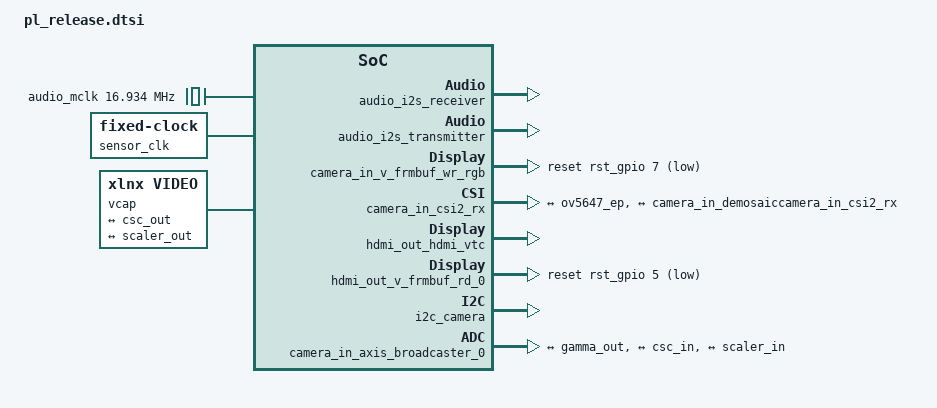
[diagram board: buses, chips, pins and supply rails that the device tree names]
/*
 * CAUTION: This file is automatically generated by Xilinx.
 * Version: XSCT 
 * Today is: Thu Jan  9 06:09:18 2025
 */
#include <dt-bindings/media/xilinx-vip.h>
#include <dt-bindings/gpio/gpio.h>


/ {
	amba_pl: amba_pl {
		#address-cells = <1>;
		#size-cells = <1>;
		compatible = "simple-bus";
		ranges ;
		audio_audio_formatter: audio_formatter@43c50000 {
			clock-names = "s_axi_lite_aclk", "m_axis_mm2s_aclk", "aud_mclk", "s_axis_s2mm_aclk";
			clocks = <&clkc 15>, <&clkc 15>, <&audio_mclk>, <&clkc 15>;
			compatible = "xlnx,audio-formatter-1.0", "xlnx,audio-formatter-1.0";
			interrupt-names = "irq_mm2s", "irq_s2mm";
			interrupt-parent = <&intc>;
			interrupts = <0 36 4 0 33 4>;
			reg = <0x43c50000 0x10000>;
			xlnx,include-mm2s = <0x1>;
			xlnx,include-s2mm = <0x1>;
			xlnx,max-num-channels-mm2s = <0x2>;
			xlnx,max-num-channels-s2mm = <0x2>;
			xlnx,mm2s-addr-width = <0x20>;
			xlnx,mm2s-async-clock = <0x0>;
			xlnx,mm2s-dataformat = <0x3>;
			xlnx,packing-mode-mm2s = <0x0>;
			xlnx,packing-mode-s2mm = <0x0>;
			xlnx,rx = <&audio_i2s_receiver>;
			xlnx,s2mm-addr-width = <0x20>;
			xlnx,s2mm-async-clock = <0x0>;
			xlnx,s2mm-dataformat = <0x1>;
			xlnx,tx = <&audio_i2s_transmitter>;
		};
		audio_mclk: audio_mclk {
			#clock-cells = <0>;
			clock-frequency = <16934404>;
			compatible = "fixed-clock";
		};
		audio_i2s_receiver: i2s_receiver@43c60000 {
			aud_mclk = <16934404>;
			clock-names = "s_axi_ctrl_aclk", "aud_mclk", "m_axis_aud_aclk";
			clocks = <&clkc 15>, <&audio_mclk>, <&clkc 15>;
			compatible = "xlnx,i2s-receiver-1.0", "xlnx,i2s-receiver-1.0";
			interrupt-names = "irq";
			interrupt-parent = <&intc>;
			interrupts = <0 35 4>;
			reg = <0x43c60000 0x10000>;
			xlnx,depth = <0x80>;
			xlnx,dwidth = <0x18>;
			xlnx,num-channels = <0x1>;
			xlnx,snd-pcm = <&audio_audio_formatter>;
		};
		audio_i2s_transmitter: i2s_transmitter@43c70000 {
			aud_mclk = <16934404>;
			clock-names = "s_axi_ctrl_aclk", "aud_mclk", "s_axis_aud_aclk";
			clocks = <&clkc 15>, <&audio_mclk>, <&clkc 15>;
			compatible = "xlnx,i2s-transmitter-1.0", "xlnx,i2s-transmitter-1.0";
			interrupt-names = "irq";
			interrupt-parent = <&intc>;
			interrupts = <0 34 4>;
			reg = <0x43c70000 0x10000>;
			xlnx,depth = <0x80>;
			xlnx,dwidth = <0x18>;
			xlnx,num-channels = <0x1>;
			xlnx,snd-pcm = <&audio_audio_formatter>;
		};
		axi_gpio_0: gpio@41210000 {
			#gpio-cells = <2>;
			clock-names = "s_axi_aclk";
			clocks = <&clkc 15>;
			compatible = "xlnx,axi-gpio-2.0", "xlnx,xps-gpio-1.00.a";
			gpio-controller ;
			reg = <0x41210000 0x10000>;
			xlnx,all-inputs = <0x0>;
			xlnx,all-inputs-2 = <0x0>;
			xlnx,all-outputs = <0x1>;
			xlnx,all-outputs-2 = <0x0>;
			xlnx,dout-default = <0x00000000>;
			xlnx,dout-default-2 = <0x00000000>;
			xlnx,gpio-width = <0x3>;
			xlnx,gpio2-width = <0x20>;
			xlnx,interrupt-present = <0x0>;
			xlnx,is-dual = <0x0>;
			xlnx,tri-default = <0xFFFFFFFF>;
			xlnx,tri-default-2 = <0xFFFFFFFF>;
		};
		vid_apclk: vid_apclk {
			#clock-cells = <0>;
			clock-frequency = <100000000>;
			compatible = "fixed-clock";
		};

		camera_in_v_frmbuf_wr_rgb: cam_preview {
			#dma-cells = <1>;
			clock-names = "ap_clk";
			clocks = <&vid_apclk>;
			compatible = "xlnx,v-frmbuf-wr-2.4", "xlnx,axi-frmbuf-wr-v2.2";
			interrupt-names = "interrupt";
			interrupt-parent = <&intc>;
			interrupts = <0 55 4>;
			reg = <0x83c20000 0x10000>;
			reset-gpios = <&rst_gpio 7 1>;
			xlnx,dma-addr-width = <32>;
			xlnx,dma-align = <16>;
			xlnx,max-height = <3072>;
			xlnx,max-width = <4096>;
			xlnx,pixels-per-clock = <2>;
			xlnx,s-axi-ctrl-addr-width = <0x7>;
			xlnx,s-axi-ctrl-data-width = <0x20>;
			xlnx,vid-formats = "rgb888", "bgr888";
			xlnx,video-width = <8>;
		};
		
		camera_in_csi2_rx: mipi_csi2_rx_subsystem@43c00000 {
			clock-names = "lite_aclk", "dphy_clk_200M", "video_aclk";
			clocks = <&clkc 15>, <&vid_apclk>, <&vid_apclk>;
			compatible = "xlnx,mipi-csi2-rx-subsystem-5.0";
			interrupt-names = "csirxss_csi_irq";
			interrupt-parent = <&intc>;
			interrupts = <0 54 4>;
			reg = <0x43c00000 0x2000>;
			video-reset-gpios = <&rst_gpio 4 1>;
			xlnx,axis-tdata-width = <32>;
			xlnx,csi-pxl-format = <0x2a>;
			xlnx,max-lanes = <2>;
			xlnx,ppc = <2>;
			xlnx,vfb ;
			mipi_csi_portscamera_in_csi2_rx: ports {
				#address-cells = <1>;
				#size-cells = <0>;
				mipi_csi_port0camera_in_csi2_rx: port@0 {
					/* Fill cfa-pattern=rggb for raw data types, other fields video-format,video-width user needs to fill */
					/* User need to add something like remote-endpoint=<&out> under the node csiss_in:endpoint */
					reg = <0>;
					xlnx,cfa-pattern = "rggb";
					xlnx,video-format = <XVIP_VF_MONO_SENSOR>;
					xlnx,video-width = <8>;
					mipi_csi_incamera_in_csi2_rx: endpoint {
						data-lanes = <1 2>;
						remote-endpoint=<&ov5647_ep>;
					};
				};
				mipi_csi_port1camera_in_csi2_rx: port@1 {
					/* Fill cfa-pattern=rggb for raw data types, other fields video-format and video-width user needs to fill */
					reg = <1>;
					xlnx,cfa-pattern = "rggb";
					xlnx,video-format = <XVIP_VF_MONO_SENSOR>;
					xlnx,video-width = <10>;
					mipi_csirx_outcamera_in_csi2_rx: endpoint {
						remote-endpoint = <&camera_in_demosaiccamera_in_csi2_rx>;
					};
				};
			};
		};
		camera_in_demosaic: demosaic {
			clock-names = "ap_clk";
			clocks = <&vid_apclk>;
			compatible = "xlnx,v-demosaic-1.1", "xlnx,v-demosaic";
			interrupt-names = "interrupt";
			interrupt-parent = <&intc>;
			interrupts = <0 30 4>;
			reg = <0x83c10000 0x10000>;
			reset-gpios = <&rst_gpio 3 1>;
			xlnx,max-height = <3072>;
			xlnx,max-width = <4096>;
			xlnx,s-axi-ctrl-addr-width = <0x6>;
			xlnx,s-axi-ctrl-data-width = <0x20>;
			demosaic_portscamera_in_demosaic: ports {
				#address-cells = <1>;
				#size-cells = <0>;
				demosaic_port0camera_in_demosaic: port@0 {
					/* For cfa-pattern=rggb user needs to fill as per BAYER format */
					reg = <0>;
					xlnx,cfa-pattern = "rggb";
					xlnx,video-width = <8>;
					camera_in_demosaiccamera_in_csi2_rx: endpoint {
						remote-endpoint = <&mipi_csirx_outcamera_in_csi2_rx>;
					};
				};
				demosaic_port1camera_in_demosaic: port@1 {
					/* For cfa-pattern=rggb user needs to fill as per BAYER format */
					reg = <1>;
					xlnx,cfa-pattern = "rggb";
					xlnx,video-width = <8>;
					demo_outcamera_in_demosaic: endpoint {
						remote-endpoint = <&camera_in_gamma_lutcamera_in_demosaic>;
					};
				};
			};
		};
		camera_in_gamma_lut: gamma_lut{
			clock-names = "ap_clk";
			clocks = <&vid_apclk>;
			compatible = "xlnx,v-gamma-lut-1.1", "xlnx,v-gamma-lut";
			interrupt-names = "interrupt";
			interrupt-parent = <&intc>;
			interrupts = <0 29 4>;
			reg = <0x83cb0000 0x10000>;
			reset-gpios = <&rst_gpio 2 1>;
			xlnx,max-height = <3072>;
			xlnx,max-width = <4096>;
			xlnx,s-axi-ctrl-addr-width = <13>;
			xlnx,s-axi-ctrl-data-width = <32>;
			gamma_portscamera_in_gamma_lut: ports {
				#address-cells = <1>;
				#size-cells = <0>;
				gamma_port0camera_in_gamma_lut: port@0 {
					reg = <0>;
					xlnx,video-width = <8>;
					camera_in_gamma_lutcamera_in_demosaic: endpoint {
						remote-endpoint = <&demo_outcamera_in_demosaic>;
					};
				};
				gamma_port1camera_in_gamma_lut: port@1 {
					reg = <1>;
					xlnx,video-width = <8>;
					gamma_out: endpoint {
						remote-endpoint = <&switch_in>;
					};
				};
			};
		};
		camera_in_frmbuf_wr: cam_capture {
			#dma-cells = <1>;
			clock-names = "ap_clk";
			clocks = <&vid_apclk>;
			compatible = "xlnx,v-frmbuf-wr-2.4", "xlnx,axi-frmbuf-wr-v2.2";
			interrupt-names = "interrupt";
			interrupt-parent = <&intc>;
			interrupts = <0 31 4>;
			reg = <0x83c40000 0x10000>;
			reset-gpios = <&rst_gpio 0 1>;
			xlnx,dma-addr-width = <32>;
			xlnx,dma-align = <16>;
			xlnx,max-height = <3072>;
			xlnx,max-width = <4096>;
			xlnx,pixels-per-clock = <2>;
			xlnx,s-axi-ctrl-addr-width = <0x7>;
			xlnx,s-axi-ctrl-data-width = <0x20>;
			xlnx,vid-formats = "rgb888", "bgr888", "y_u_v8";
			xlnx,video-width = <8>;
		};
		clk_wiz_0: clk_wiz@43c30000 {
			#clock-cells = <1>;
			clock-names = "s_axi_aclk", "clk_in1";
			clock-output-names = "0x43c30000-mlck";
			clocks = <&clkc 15>, <&clkc 15>;
			compatible = "xlnx,clk-wiz-6.0", "xlnx,clocking-wizard";
			reg = <0x43c30000 0x10000>;
			xlnx,nr-outputs = <1>;
			xlnx,speed-grade = <2>;
		};
		hdmi_out_clk_wiz_dyn: clk_wiz@43c80000 {
			#clock-cells = <1>;
			clock-names = "s_axi_aclk", "clk_in1";
			clock-output-names = "0x43c80000-hdmi_pclk", "0x43c80000-hdmi_pclk_5x";
			clocks = <&clkc 15>, <&clkc 15>;
			compatible = "xlnx,clk-wiz-6.0", "xlnx,clocking-wizard";
			reg = <0x43c80000 0x10000>;
			xlnx,nr-outputs = <2>;
			xlnx,speed-grade = <2>;
		};
		hdmi_out_hdmi_vtc: v_tc@43c90000 {
			clock-names = "clk", "s_axi_aclk";
			clocks = <&hdmi_pclk>, <&clkc 15>;
			compatible = "xlnx,v-tc-6.2", "xlnx,v-tc-6.1";
			interrupt-names = "irq";
			interrupt-parent = <&intc>;
			interrupts = <0 53 4>;
			reg = <0x43c90000 0x10000>;
			xlnx,generator ;
		};
		hdmi_pclk: hdmi_pclk {
			#clock-cells = <0>;
			clock-frequency = <148500000>;
			compatible = "fixed-clock";
		};
		hdmi_pclk_5x: hdmi_pclk_5x {
			#clock-cells = <0>;
			clock-frequency = <742500000>;
			compatible = "fixed-clock";
		};
		sensor_clk: sensor_clk {
			#clock-cells = <0>;
			clock-frequency = <25000000>;
			compatible = "fixed-clock";
		};
		hdmi_out_v_frmbuf_rd_0: v_frmbuf_rd@43ca0000 {
			#dma-cells = <1>;
			clock-names = "ap_clk";
			clocks = <&hdmi_pclk>;
			compatible = "xlnx,axi-frmbuf-rd-v2.2";
			interrupt-names = "interrupt";
			interrupt-parent = <&intc>;
			interrupts = <0 52 4>;
			reg = <0x43ca0000 0x10000>;
			reset-gpios = <&rst_gpio 5 1>;
			xlnx,dma-addr-width = <32>;
			xlnx,dma-align = <8>;
			xlnx,max-height = <1080>;
			xlnx,max-width = <1920>;
			xlnx,pixels-per-clock = <1>;
			xlnx,s-axi-ctrl-addr-width = <0x7>;
			xlnx,s-axi-ctrl-data-width = <0x20>;
			xlnx,vid-formats = "rgb888", "bgr888";
			xlnx,video-width = <8>;
		};
		i2c_camera: i2c@41600000 {
			#address-cells = <1>;
			#size-cells = <0>;
			clock-names = "s_axi_aclk";
			clocks = <&clkc 15>;
			compatible = "xlnx,axi-iic-2.1", "xlnx,xps-iic-2.00.a";
			interrupt-names = "iic2intc_irpt";
			interrupt-parent = <&intc>;
			interrupts = <0 32 4>;
			reg = <0x41600000 0x10000>;
		};
		rst_gpio: gpio@41220000 {
			#gpio-cells = <2>;
			clock-names = "s_axi_aclk";
			clocks = <&clkc 15>;
			compatible = "xlnx,axi-gpio-2.0", "xlnx,xps-gpio-1.00.a";
			gpio-controller ;
			reg = <0x41220000 0x10000>;
			xlnx,all-inputs = <0x0>;
			xlnx,all-inputs-2 = <0x0>;
			xlnx,all-outputs = <0x1>;
			xlnx,all-outputs-2 = <0x0>;
			xlnx,dout-default = <0x00000000>;
			xlnx,dout-default-2 = <0x00000000>;
			xlnx,gpio-width = <0x8>;
			xlnx,gpio2-width = <0x20>;
			xlnx,interrupt-present = <0x0>;
			xlnx,is-dual = <0x0>;
			xlnx,tri-default = <0xFFFFFFFF>;
			xlnx,tri-default-2 = <0xFFFFFFFF>;
		};
	
		camera_in_axis_broadcaster_0: axis_broadcastercamera_in_axis_broadcaster_0@0 {
			compatible = "xlnx,axis-broadcaster-1.1";
			axis_broadcaster_portscamera_in_axis_broadcaster_0: ports {
				#address-cells = <1>;
				#size-cells = <0>;
				axis_broad_port1camera_in_axis_broadcaster_0: port@0 {
					reg = <0>;
					switch_in: endpoint {
						remote-endpoint = <&gamma_out>;
					};	
				};
				axis_broad_port1camera_in_axis_broadcaster_1: port@1 {
					reg = <1>;
					switch_out_csc: endpoint {
						remote-endpoint = <&csc_in>;
					};
				};
				axis_broad_port2camera_in_axis_broadcaster_2: port@2 {
					reg = <2>;
					switch_out_scaler: endpoint {
						remote-endpoint = <&scaler_in>;
					};
				};
			};
		};

		camera_in_scaler_display: vpss_scaler {
			clock-names = "aclk_axis", "aclk_ctrl";
			clocks = <&vid_apclk>, <&clkc 15>;
			compatible = "xlnx,v-vpss-scaler-2.2";
			reg = <0x43d00000 0x40000>;
			reset-gpios = <&rst_gpio 1 1>;
			xlnx,colorspace-support = <2>;
			xlnx,csc-enable-window = "true";
			xlnx,enable-csc = "false";
			xlnx,h-scaler-phases = <64>;
			xlnx,h-scaler-taps = <4>;
			xlnx,max-height = <3072>;
			xlnx,max-num-phases = <64>;
			xlnx,max-width = <4096>;
			xlnx,num-hori-taps = <4>;
			xlnx,num-vert-taps = <4>;
			xlnx,pix-per-clk = <2>;
			xlnx,samples-per-clk = <2>;
			xlnx,scaler-algorithm = <0>;
			xlnx,topology = <0>;
			xlnx,use-uram = <0>;
			xlnx,v-scaler-phases = <64>;
			xlnx,v-scaler-taps = <4>;
			xlnx,video-width = <8>;
			scaler_portscamera_in_v_proc_ss_display: ports {
				#address-cells = <1>;
				#size-cells = <0>;
				scaler_port0camera_in_v_proc_ss_display: port@0 {
					/* For xlnx,video-format user needs to fill as per their requirement */
					reg = <0>;
					xlnx,video-format = <XVIP_VF_RBG>;
					xlnx,video-width = <8>;
					scaler_in: endpoint {
						remote-endpoint = <&switch_out_scaler>;
					};
				};
				scaler_port1camera_in_v_proc_ss_display: port@1 {
					/* For xlnx,video-format user needs to fill as per their requirement */
					reg = <1>;
					xlnx,video-format = <XVIP_VF_RBG>;
					xlnx,video-width = <8>;
					scaler_out: endpoint {
						remote-endpoint = <&frmbuf_wr_preview>;
					};
				};
			};
		};

		camera_in_vpss: vpss_csc {
			clock-names = "aclk";
			clocks = <&vid_apclk>;
			compatible = "xlnx,v-vpss-csc";
			reg = <0x83cc0000 0x10000>;
			reset-gpios = <&rst_gpio 6 1>;
			xlnx,colorspace-support = <0>;
			xlnx,csc-enable-window = "false";
			xlnx,max-height = <3072>;
			xlnx,max-width = <4096>;
			xlnx,num-video-components = <3>;
			xlnx,samples-per-clk = <2>;
			xlnx,topology = <3>;
			xlnx,use-uram = <0>;
			xlnx,video-width = <8>;
			csc_portscamera_in_vpss: ports {
				#address-cells = <1>;
				#size-cells = <0>;
				csc_port0camera_in_vpss: port@0 {
					/* For xlnx,video-format user needs to fill as per their requirement */
					reg = <0>;
					xlnx,video-format = <XVIP_VF_RBG>;
					xlnx,video-width = <8>;
					csc_in: endpoint {
						remote-endpoint = <&switch_out_csc>;
					};
				};
			csc_port1camera_in_vpss: port@1 {
				/* For xlnx,video-format user needs to fill as per their requirement */
				reg = <1>;
				xlnx,video-format = <XVIP_VF_RBG>;
				xlnx,video-width = <8>;
				csc_out: endpoint {
						remote-endpoint = <&frmbuf_wr_camera>;
					};
				};
			};
		};

	vcap {
		compatible = "xlnx,video";
            xlnx,atomic_streamon;
            dma-names = "port0", "port1";
            dmas = <&camera_in_frmbuf_wr 0>, <&camera_in_v_frmbuf_wr_rgb 0>;
            
            vcap_ports_camera_in: ports {
                #address-cells = <1>;
                #size-cells = <0>;
                
                /* Port 0: CSC path to ? */
                vcap_port0_camera_in: port@0 {
                    direction = "input";
                    reg = <0>;
                    frmbuf_wr_camera: endpoint {
                        remote-endpoint = <&csc_out>;
                    };
                };
                
                /* Port 1: Scaler path to RGB */
                vcap_port1_camera_in: port@1 {
                    direction = "input";
                    reg = <1>;
                    frmbuf_wr_preview: endpoint {
                        remote-endpoint = <&scaler_out>;
                    };
                };
            };
        };
	};
};
